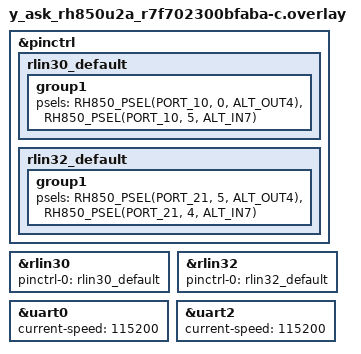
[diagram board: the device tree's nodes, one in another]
/*
 * Copyright (c) 2026 Renesas Electronics Corporation
 *
 * SPDX-License-Identifier: Apache-2.0
 */

&pinctrl {
	rlin30_default: rlin30_default {
		group1 {
			psels = <RH850_PSEL(PORT_10, 0, ALT_OUT4)>,
				<RH850_PSEL(PORT_10, 5, ALT_IN7)>;
		};
	};

	rlin32_default: rlin32_default {
		group1 {
			psels = <RH850_PSEL(PORT_21, 5, ALT_OUT4)>,
				<RH850_PSEL(PORT_21, 4, ALT_IN7)>;
		};
	};
};

&rlin30 {
	pinctrl-0 = <&rlin30_default>;
	pinctrl-names = "default";
	status = "okay";
};

&rlin32 {
	pinctrl-0 = <&rlin32_default>;
	pinctrl-names = "default";
	status = "okay";
};

dut: &uart0 {
	status = "okay";
	current-speed = <115200>;
};

dut_aux: &uart2 {
	status = "okay";
	current-speed = <115200>;
};
